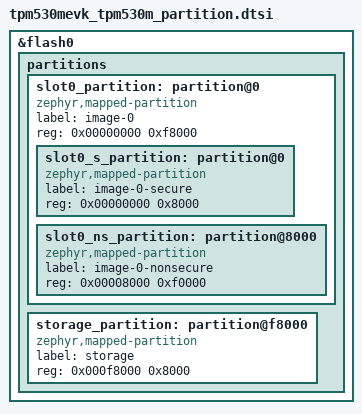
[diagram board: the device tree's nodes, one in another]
/*
 * Copyright (c) 2026 Nordic Semiconductor ASA
 *
 * SPDX-License-Identifier: LicenseRef-Nordic-5-Clause
 */

&flash0 {
	/*
	 * 0x0000_0000  Primary area			(992 kB)
	 *   0x0000_0000  Primary secure image		( 32 kB)
	 *   0x0000_8000  Primary non-secure image	(960 kB)
	 * 0x000f_8000  Settings storage		( 32 kB)
	 */
	partitions {
		ranges;
		#address-cells = <1>;
		#size-cells = <1>;

		slot0_partition: partition@0 {
			compatible = "zephyr,mapped-partition";
			label = "image-0";
			reg = <0x00000000 0xf8000>;
			ranges = <0x0 0x00000000 0xf8000>;
			#address-cells = <1>;
			#size-cells = <1>;

			slot0_s_partition: partition@0 {
				compatible = "zephyr,mapped-partition";
				label = "image-0-secure";
				reg = <0x00000000 0x8000>;
			};

			slot0_ns_partition: partition@8000 {
				compatible = "zephyr,mapped-partition";
				label = "image-0-nonsecure";
				reg = <0x00008000 0xf0000>;
			};
		};

		storage_partition: partition@f8000 {
			compatible = "zephyr,mapped-partition";
			label = "storage";
			reg = <0x000f8000 0x8000>;
		};
	};
};

#include <common/nordic/nrf91_partition_sram.dtsi>
